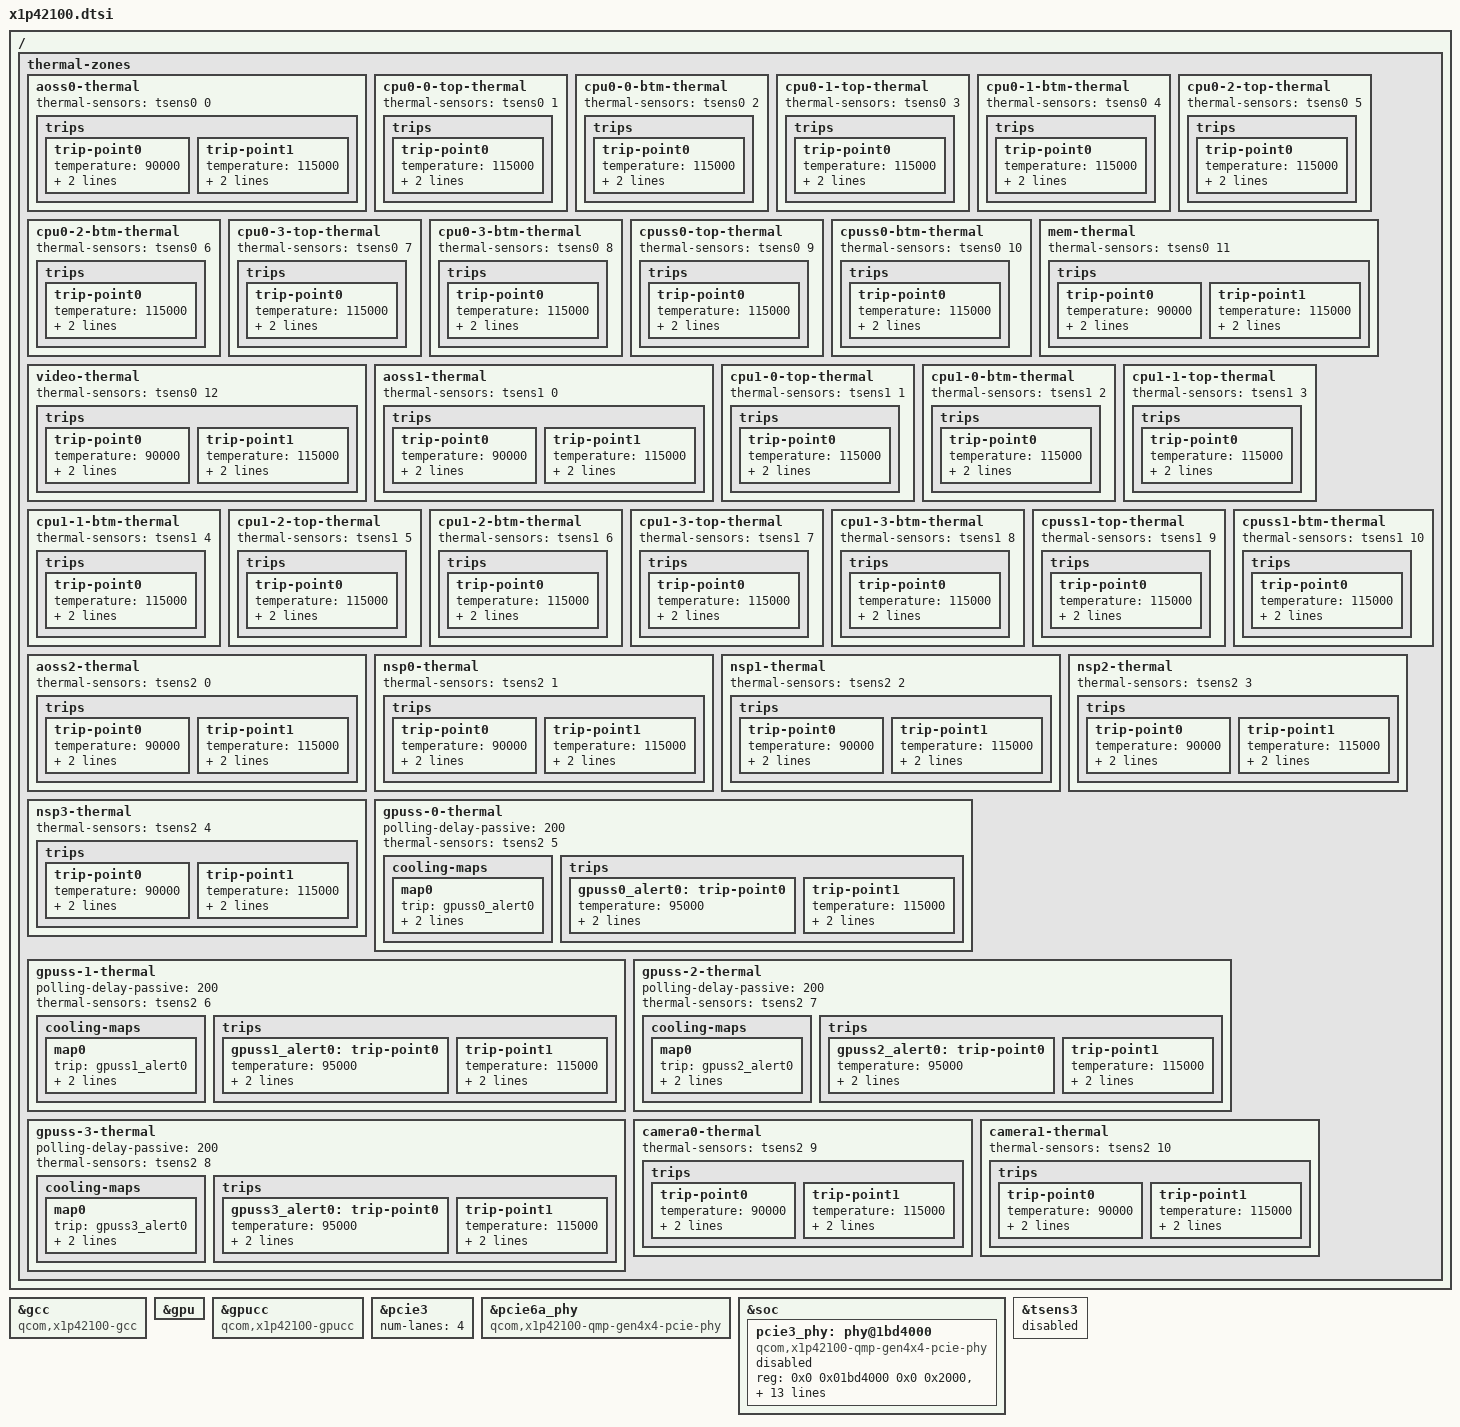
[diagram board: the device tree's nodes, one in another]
// SPDX-License-Identifier: BSD-3-Clause
/*
 * Copyright (c) 2025 Qualcomm Innovation Center, Inc. All rights reserved.
 */

/* X1P42100 is heavily based on X1E80100, with some meaningful differences */
#include "x1e80100.dtsi"

/delete-node/ &bwmon_cluster0;
/delete-node/ &cluster_pd2;
/delete-node/ &cpu_map_cluster2;
/delete-node/ &cpu8;
/delete-node/ &cpu9;
/delete-node/ &cpu10;
/delete-node/ &cpu11;
/delete-node/ &cpu_pd8;
/delete-node/ &cpu_pd9;
/delete-node/ &cpu_pd10;
/delete-node/ &cpu_pd11;
/delete-node/ &pcie3_phy;
/delete-node/ &thermal_zones;

&gcc {
	compatible = "qcom,x1p42100-gcc", "qcom,x1e80100-gcc";
};

/* The GPU is physically different and will be brought up later */
&gpu {
	/delete-property/ compatible;
};

&gpucc {
	compatible = "qcom,x1p42100-gpucc";
};

/* PCIe3 has half the lanes compared to X1E80100 */
&pcie3 {
	num-lanes = <4>;
};

&pcie6a_phy {
	compatible = "qcom,x1p42100-qmp-gen4x4-pcie-phy";
};

&soc {
	/* The PCIe3 PHY on X1P42100 uses a different IP block */
	pcie3_phy: phy@1bd4000 {
		compatible = "qcom,x1p42100-qmp-gen4x4-pcie-phy";
		reg = <0x0 0x01bd4000 0x0 0x2000>,
		      <0x0 0x01bd6000 0x0 0x2000>;

		clocks = <&gcc GCC_PCIE_3_PHY_AUX_CLK>,
			 <&gcc GCC_PCIE_3_CFG_AHB_CLK>,
			 <&tcsr TCSR_PCIE_8L_CLKREF_EN>,
			 <&gcc GCC_PCIE_3_PHY_RCHNG_CLK>,
			 <&gcc GCC_PCIE_3_PIPE_CLK>,
			 <&gcc GCC_PCIE_3_PIPEDIV2_CLK>;
		clock-names = "aux",
			      "cfg_ahb",
			      "ref",
			      "rchng",
			      "pipe",
			      "pipediv2";

		resets = <&gcc GCC_PCIE_3_PHY_BCR>,
			 <&gcc GCC_PCIE_3_NOCSR_COM_PHY_BCR>;
		reset-names = "phy",
			      "phy_nocsr";

		assigned-clocks = <&gcc GCC_PCIE_3_PHY_RCHNG_CLK>;
		assigned-clock-rates = <100000000>;

		power-domains = <&gcc GCC_PCIE_3_PHY_GDSC>;

		#clock-cells = <0>;
		clock-output-names = "pcie3_pipe_clk";

		#phy-cells = <0>;

		status = "disabled";
	};
};

/* While physically present, this controller is left unconfigured and unused */
&tsens3 {
	status = "disabled";
};

/ {
	thermal-zones {
		aoss0-thermal {
			thermal-sensors = <&tsens0 0>;

			trips {
				trip-point0 {
					temperature = <90000>;
					hysteresis = <2000>;
					type = "hot";
				};

				trip-point1 {
					temperature = <115000>;
					hysteresis = <1000>;
					type = "critical";
				};
			};
		};

		cpu0-0-top-thermal {
			thermal-sensors = <&tsens0 1>;

			trips {
				trip-point0 {
					temperature = <115000>;
					hysteresis = <1000>;
					type = "critical";
				};
			};
		};

		cpu0-0-btm-thermal {
			thermal-sensors = <&tsens0 2>;

			trips {
				trip-point0 {
					temperature = <115000>;
					hysteresis = <1000>;
					type = "critical";
				};
			};
		};

		cpu0-1-top-thermal {
			thermal-sensors = <&tsens0 3>;

			trips {
				trip-point0 {
					temperature = <115000>;
					hysteresis = <1000>;
					type = "critical";
				};
			};
		};

		cpu0-1-btm-thermal {
			thermal-sensors = <&tsens0 4>;

			trips {
				trip-point0 {
					temperature = <115000>;
					hysteresis = <1000>;
					type = "critical";
				};
			};
		};

		cpu0-2-top-thermal {
			thermal-sensors = <&tsens0 5>;

			trips {
				trip-point0 {
					temperature = <115000>;
					hysteresis = <1000>;
					type = "critical";
				};
			};
		};

		cpu0-2-btm-thermal {
			thermal-sensors = <&tsens0 6>;

			trips {
				trip-point0 {
					temperature = <115000>;
					hysteresis = <1000>;
					type = "critical";
				};
			};
		};

		cpu0-3-top-thermal {
			thermal-sensors = <&tsens0 7>;

			trips {
				trip-point0 {
					temperature = <115000>;
					hysteresis = <1000>;
					type = "critical";
				};
			};
		};

		cpu0-3-btm-thermal {
			thermal-sensors = <&tsens0 8>;

			trips {
				trip-point0 {
					temperature = <115000>;
					hysteresis = <1000>;
					type = "critical";
				};
			};
		};

		cpuss0-top-thermal {
			thermal-sensors = <&tsens0 9>;

			trips {
				trip-point0 {
					temperature = <115000>;
					hysteresis = <1000>;
					type = "critical";
				};
			};
		};

		cpuss0-btm-thermal {
			thermal-sensors = <&tsens0 10>;

			trips {
				trip-point0 {
					temperature = <115000>;
					hysteresis = <1000>;
					type = "critical";
				};
			};
		};

		mem-thermal {
			thermal-sensors = <&tsens0 11>;

			trips {
				trip-point0 {
					temperature = <90000>;
					hysteresis = <2000>;
					type = "hot";
				};

				trip-point1 {
					temperature = <115000>;
					hysteresis = <0>;
					type = "critical";
				};
			};
		};

		video-thermal {
			thermal-sensors = <&tsens0 12>;

			trips {
				trip-point0 {
					temperature = <90000>;
					hysteresis = <2000>;
					type = "hot";
				};

				trip-point1 {
					temperature = <115000>;
					hysteresis = <1000>;
					type = "critical";
				};
			};
		};

		aoss1-thermal {
			thermal-sensors = <&tsens1 0>;

			trips {
				trip-point0 {
					temperature = <90000>;
					hysteresis = <2000>;
					type = "hot";
				};

				trip-point1 {
					temperature = <115000>;
					hysteresis = <1000>;
					type = "critical";
				};
			};
		};

		cpu1-0-top-thermal {
			thermal-sensors = <&tsens1 1>;

			trips {
				trip-point0 {
					temperature = <115000>;
					hysteresis = <1000>;
					type = "critical";
				};
			};
		};

		cpu1-0-btm-thermal {
			thermal-sensors = <&tsens1 2>;

			trips {
				trip-point0 {
					temperature = <115000>;
					hysteresis = <1000>;
					type = "critical";
				};
			};
		};

		cpu1-1-top-thermal {
			thermal-sensors = <&tsens1 3>;

			trips {
				trip-point0 {
					temperature = <115000>;
					hysteresis = <1000>;
					type = "critical";
				};
			};
		};

		cpu1-1-btm-thermal {
			thermal-sensors = <&tsens1 4>;

			trips {
				trip-point0 {
					temperature = <115000>;
					hysteresis = <1000>;
					type = "critical";
				};
			};
		};

		cpu1-2-top-thermal {
			thermal-sensors = <&tsens1 5>;

			trips {
				trip-point0 {
					temperature = <115000>;
					hysteresis = <1000>;
					type = "critical";
				};
			};
		};

		cpu1-2-btm-thermal {
			thermal-sensors = <&tsens1 6>;

			trips {
				trip-point0 {
					temperature = <115000>;
					hysteresis = <1000>;
					type = "critical";
				};
			};
		};

		cpu1-3-top-thermal {
			thermal-sensors = <&tsens1 7>;

			trips {
				trip-point0 {
					temperature = <115000>;
					hysteresis = <1000>;
					type = "critical";
				};
			};
		};

		cpu1-3-btm-thermal {
			thermal-sensors = <&tsens1 8>;

			trips {
				trip-point0 {
					temperature = <115000>;
					hysteresis = <1000>;
					type = "critical";
				};
			};
		};

		cpuss1-top-thermal {
			thermal-sensors = <&tsens1 9>;

			trips {
				trip-point0 {
					temperature = <115000>;
					hysteresis = <1000>;
					type = "critical";
				};
			};
		};

		cpuss1-btm-thermal {
			thermal-sensors = <&tsens1 10>;

			trips {
				trip-point0 {
					temperature = <115000>;
					hysteresis = <1000>;
					type = "critical";
				};
			};
		};

		aoss2-thermal {
			thermal-sensors = <&tsens2 0>;

			trips {
				trip-point0 {
					temperature = <90000>;
					hysteresis = <2000>;
					type = "hot";
				};

				trip-point1 {
					temperature = <115000>;
					hysteresis = <1000>;
					type = "critical";
				};
			};
		};

		nsp0-thermal {
			thermal-sensors = <&tsens2 1>;

			trips {
				trip-point0 {
					temperature = <90000>;
					hysteresis = <2000>;
					type = "hot";
				};

				trip-point1 {
					temperature = <115000>;
					hysteresis = <1000>;
					type = "critical";
				};
			};
		};

		nsp1-thermal {
			thermal-sensors = <&tsens2 2>;

			trips {
				trip-point0 {
					temperature = <90000>;
					hysteresis = <2000>;
					type = "hot";
				};

				trip-point1 {
					temperature = <115000>;
					hysteresis = <1000>;
					type = "critical";
				};
			};
		};

		nsp2-thermal {
			thermal-sensors = <&tsens2 3>;

			trips {
				trip-point0 {
					temperature = <90000>;
					hysteresis = <2000>;
					type = "hot";
				};

				trip-point1 {
					temperature = <115000>;
					hysteresis = <1000>;
					type = "critical";
				};
			};
		};

		nsp3-thermal {
			thermal-sensors = <&tsens2 4>;

			trips {
				trip-point0 {
					temperature = <90000>;
					hysteresis = <2000>;
					type = "hot";
				};

				trip-point1 {
					temperature = <115000>;
					hysteresis = <1000>;
					type = "critical";
				};
			};
		};

		gpuss-0-thermal {
			polling-delay-passive = <200>;

			thermal-sensors = <&tsens2 5>;

			cooling-maps {
				map0 {
					trip = <&gpuss0_alert0>;
					cooling-device = <&gpu THERMAL_NO_LIMIT THERMAL_NO_LIMIT>;
				};
			};

			trips {
				gpuss0_alert0: trip-point0 {
					temperature = <95000>;
					hysteresis = <1000>;
					type = "passive";
				};

				trip-point1 {
					temperature = <115000>;
					hysteresis = <1000>;
					type = "critical";
				};
			};
		};

		gpuss-1-thermal {
			polling-delay-passive = <200>;

			thermal-sensors = <&tsens2 6>;

			cooling-maps {
				map0 {
					trip = <&gpuss1_alert0>;
					cooling-device = <&gpu THERMAL_NO_LIMIT THERMAL_NO_LIMIT>;
				};
			};

			trips {
				gpuss1_alert0: trip-point0 {
					temperature = <95000>;
					hysteresis = <1000>;
					type = "passive";
				};

				trip-point1 {
					temperature = <115000>;
					hysteresis = <1000>;
					type = "critical";
				};
			};
		};

		gpuss-2-thermal {
			polling-delay-passive = <200>;

			thermal-sensors = <&tsens2 7>;

			cooling-maps {
				map0 {
					trip = <&gpuss2_alert0>;
					cooling-device = <&gpu THERMAL_NO_LIMIT THERMAL_NO_LIMIT>;
				};
			};

			trips {
				gpuss2_alert0: trip-point0 {
					temperature = <95000>;
					hysteresis = <1000>;
					type = "passive";
				};

				trip-point1 {
					temperature = <115000>;
					hysteresis = <1000>;
					type = "critical";
				};
			};
		};

		gpuss-3-thermal {
			polling-delay-passive = <200>;

			thermal-sensors = <&tsens2 8>;

			cooling-maps {
				map0 {
					trip = <&gpuss3_alert0>;
					cooling-device = <&gpu THERMAL_NO_LIMIT THERMAL_NO_LIMIT>;
				};
			};

			trips {
				gpuss3_alert0: trip-point0 {
					temperature = <95000>;
					hysteresis = <1000>;
					type = "passive";
				};

				trip-point1 {
					temperature = <115000>;
					hysteresis = <1000>;
					type = "critical";
				};
			};
		};

		camera0-thermal {
			thermal-sensors = <&tsens2 9>;

			trips {
				trip-point0 {
					temperature = <90000>;
					hysteresis = <2000>;
					type = "hot";
				};

				trip-point1 {
					temperature = <115000>;
					hysteresis = <1000>;
					type = "critical";
				};
			};
		};

		camera1-thermal {
			thermal-sensors = <&tsens2 10>;

			trips {
				trip-point0 {
					temperature = <90000>;
					hysteresis = <2000>;
					type = "hot";
				};

				trip-point1 {
					temperature = <115000>;
					hysteresis = <1000>;
					type = "critical";
				};
			};
		};
	};
};
